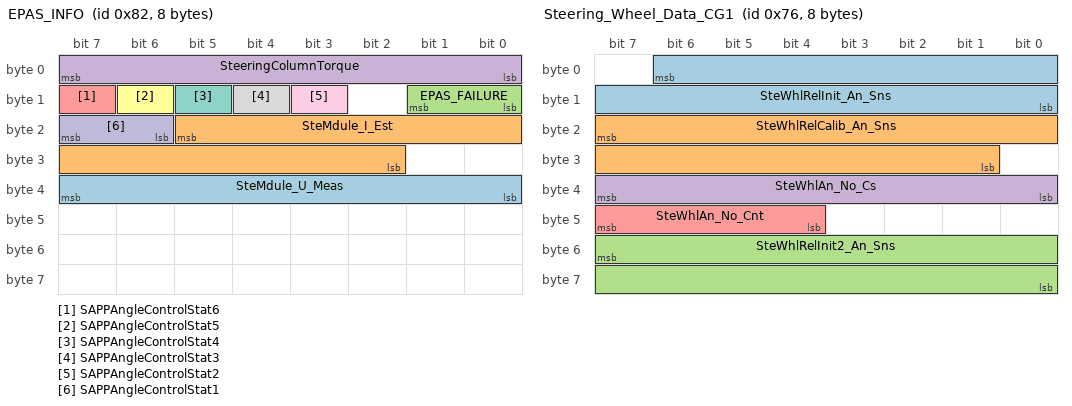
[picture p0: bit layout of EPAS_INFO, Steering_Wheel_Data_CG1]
BO_ 130 EPAS_INFO: 8 XXX
 SG_ SteMdule_U_Meas : 39|8@0+ (0.05,6.0) [0|0] "Volts" XXX
 SG_ SteMdule_I_Est : 21|12@0+ (0.05,-64.0) [0|0] "Amps" XXX
 SG_ EPAS_FAILURE : 9|2@0+ (1,0) [0|0] "" XXX
 SG_ SteeringColumnTorque : 7|8@0+ (0.0625,-8.0) [0|0] "Nm" XXX
 SG_ SAPPAngleControlStat6 : 15|1@0+ (1,0) [0|0] "" XXX
 SG_ SAPPAngleControlStat5 : 14|1@0+ (1,0) [0|0] "" XXX
 SG_ SAPPAngleControlStat4 : 13|1@0+ (1,0) [0|0] "" XXX
 SG_ SAPPAngleControlStat3 : 12|1@0+ (1,0) [0|0] "" XXX
 SG_ SAPPAngleControlStat2 : 11|1@0+ (1,0) [0|0] "" XXX
 SG_ SAPPAngleControlStat1 : 23|2@0+ (1,0) [0|0] "" XXX

BO_ 118 Steering_Wheel_Data_CG1: 8 XXX
 SG_ SteWhlRelInit_An_Sns : 6|15@0+ (0.1,-1600.0) [0|0] "deg" XXX
 SG_ SteWhlRelCalib_An_Sns : 23|15@0+ (0.1,-1600.0) [0|0] "deg" XXX
 SG_ SteWhlRelInit2_An_Sns : 55|16@0+ (0.1,-3200.0) [0|0] "deg" XXX
 SG_ SteWhlAn_No_Cs : 39|8@0+ (1,0) [0|0] "" XXX
 SG_ SteWhlAn_No_Cnt : 47|4@0+ (1,0) [0|0] "Counts" XXX

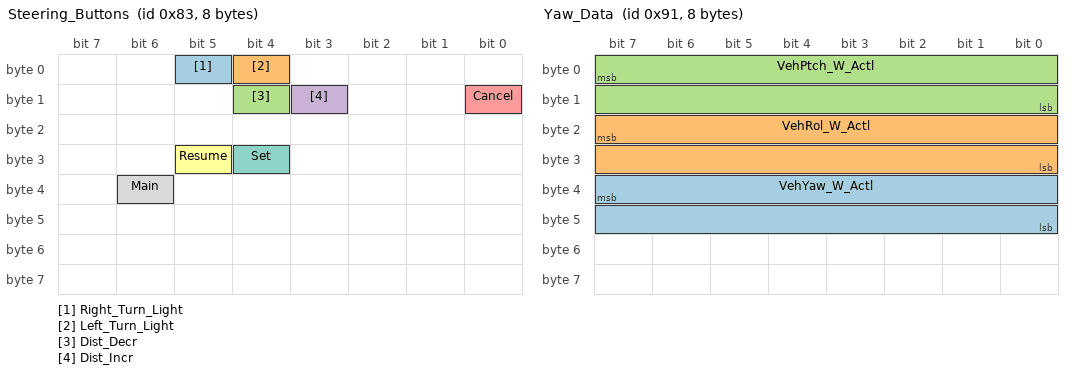
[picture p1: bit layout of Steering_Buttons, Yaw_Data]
BO_ 131 Steering_Buttons: 8 XXX
 SG_ Right_Turn_Light : 5|1@0+ (1,0) [0|0] "" XXX
 SG_ Left_Turn_Light : 4|1@0+ (1,0) [0|0] "" XXX
 SG_ Dist_Decr : 12|1@0+ (1,0) [0|0] "" XXX
 SG_ Dist_Incr : 11|1@0+ (1,0) [0|0] "" XXX
 SG_ Cancel : 8|1@0+ (1,0) [0|0] "" XXX
 SG_ Resume : 29|1@0+ (1,0) [0|0] "" XXX
 SG_ Set : 28|1@0+ (1,0) [0|0] "" XXX
 SG_ Main : 38|1@0+ (1,0) [0|0] "" XXX

BO_ 145 Yaw_Data: 8 XXX
 SG_ VehYaw_W_Actl : 39|16@0+ (0.0002,-6.5) [0|0] "rad/s" XXX
 SG_ VehRol_W_Actl : 23|16@0+ (0.0002,-6.5) [0|0] "rad/s" XXX
 SG_ VehPtch_W_Actl : 7|16@0+ (0.0002,-6.5) [0|0] "rad/s" XXX

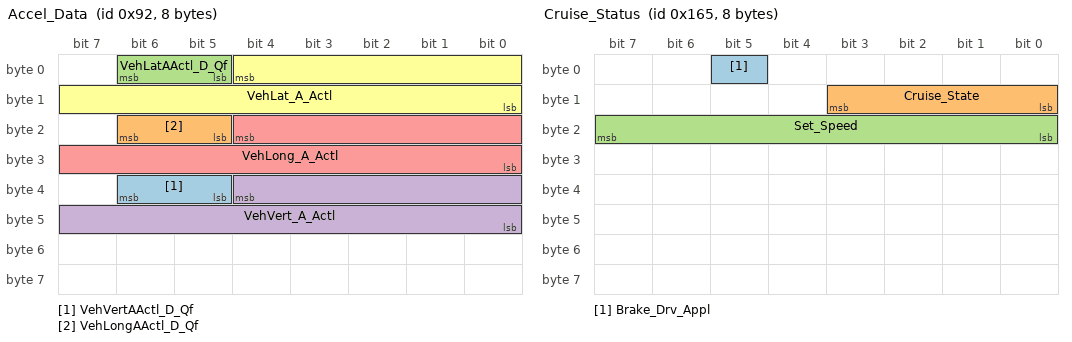
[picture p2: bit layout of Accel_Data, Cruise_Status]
BO_ 146 Accel_Data: 8 XXX
 SG_ VehVertAActl_D_Qf : 38|2@0+ (1,0) [0|0] "" XXX
 SG_ VehLongAActl_D_Qf : 22|2@0+ (1,0) [0|0] "" XXX
 SG_ VehLatAActl_D_Qf : 6|2@0+ (1,0) [0|0] "" XXX
 SG_ VehVert_A_Actl : 36|13@0+ (0.01,-40.0) [0|0] "m/s^2" XXX
 SG_ VehLong_A_Actl : 20|13@0+ (0.01,-40.0) [0|0] "m/s^2" XXX
 SG_ VehLat_A_Actl : 4|13@0+ (0.01,-40.0) [0|0] "m/s^2" XXX

BO_ 357 Cruise_Status: 8 XXX
 SG_ Brake_Drv_Appl : 5|1@0+ (1,0) [0|0] "" XXX
 SG_ Cruise_State : 11|4@0+ (1,0) [0|0] "" XXX
 SG_ Set_Speed : 23|8@0+ (1,0) [0|0] "" XXX

BO_ 516 EngineData_14: 8 XXX
 SG_ ApedPosScal_Pc_Actl : 1|10@0+ (0.1,0) [0|0] "%" XXX

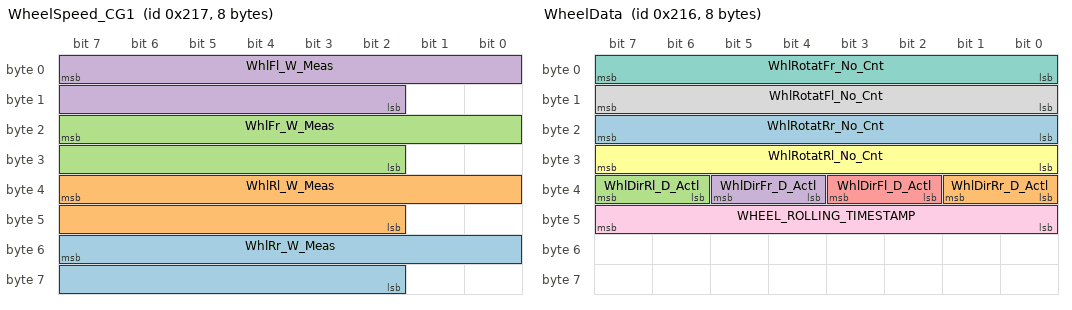
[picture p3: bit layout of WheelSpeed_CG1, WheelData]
BO_ 535 WheelSpeed_CG1: 8 XXX
 SG_ WhlRr_W_Meas : 55|14@0+ (0.04,0) [0|0] "rad/s" XXX
 SG_ WhlRl_W_Meas : 39|14@0+ (0.04,0) [0|0] "rad/s" XXX
 SG_ WhlFr_W_Meas : 23|14@0+ (0.04,0) [0|0] "rad/s" XXX
 SG_ WhlFl_W_Meas : 7|14@0+ (0.04,0) [0|0] "rad/s" XXX

BO_ 534 WheelData: 8 XXX
 SG_ WhlRotatRr_No_Cnt : 23|8@0+ (1,0) [0|0] "" XXX
 SG_ WhlDirRr_D_Actl : 33|2@0+ (1,0) [0|0] "" XXX
 SG_ WhlDirRl_D_Actl : 39|2@0+ (1,0) [0|0] "" XXX
 SG_ WhlDirFr_D_Actl : 37|2@0+ (1,0) [0|0] "" XXX
 SG_ WhlDirFl_D_Actl : 35|2@0+ (1,0) [0|0] "" XXX
 SG_ WhlRotatRl_No_Cnt : 31|8@0+ (1,0) [0|0] "" XXX
 SG_ WhlRotatFr_No_Cnt : 7|8@0+ (1,0) [0|0] "" XXX
 SG_ WhlRotatFl_No_Cnt : 15|8@0+ (1,0) [0|0] "" XXX
 SG_ WHEEL_ROLLING_TIMESTAMP : 47|8@0+ (1,0) [0|0] "" XXX

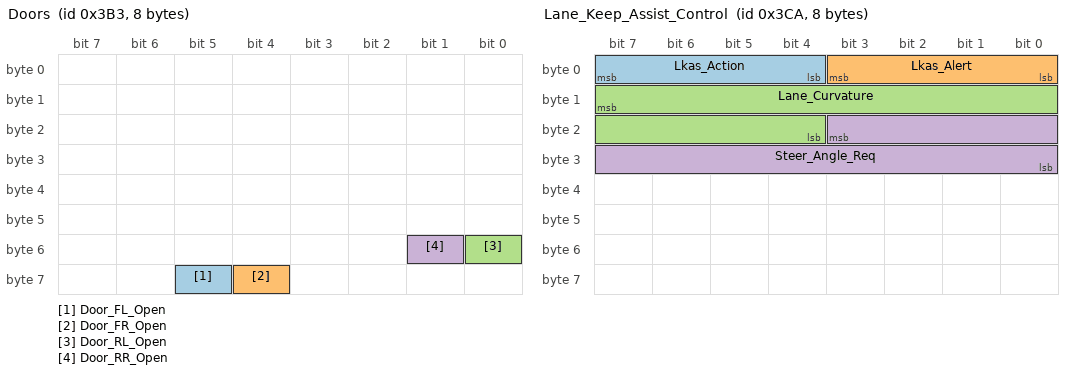
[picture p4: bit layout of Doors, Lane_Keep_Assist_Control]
BO_ 947 Doors: 8 XXX
 SG_ Door_FL_Open : 61|1@0+ (1,0) [0|0] "" XXX
 SG_ Door_FR_Open : 60|1@0+ (1,0) [0|0] "" XXX
 SG_ Door_RL_Open : 48|1@0+ (1,0) [0|0] "" XXX
 SG_ Door_RR_Open : 49|1@0+ (1,0) [0|0] "" XXX

BO_ 963 BCM_to_HS_Body: 8 XXX
 SG_ Brake_Lights : 8|1@0+ (1,0) [0|0] "" XXX

BO_ 970 Lane_Keep_Assist_Control: 8 XXX
 SG_ Lkas_Action : 7|4@0+ (1,0) [0|15] "" XXX
 SG_ Lkas_Alert : 3|4@0+ (1,0) [0|15] "" XXX
 SG_ Lane_Curvature : 15|12@0+ (5e-06,-0.01) [0|0] "1/m" XXX
 SG_ Steer_Angle_Req : 19|12@0+ (0.04297,-88.00445) [0|0] "deg" XXX

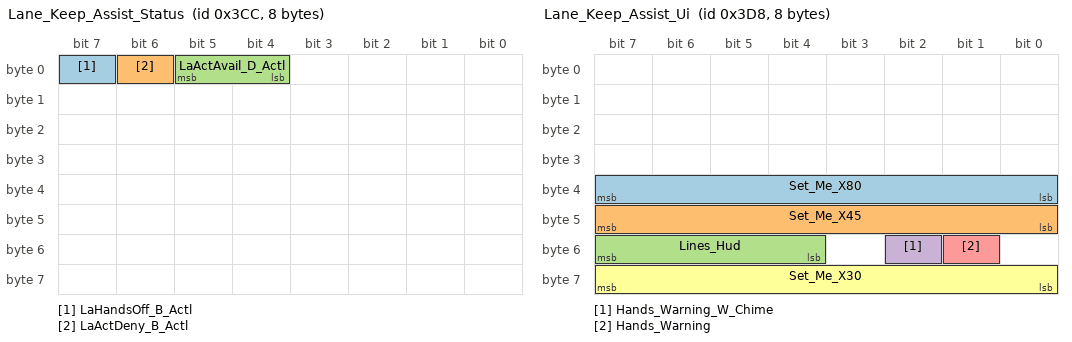
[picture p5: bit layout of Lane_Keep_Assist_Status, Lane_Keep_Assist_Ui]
BO_ 972 Lane_Keep_Assist_Status: 8 XXX
 SG_ LaHandsOff_B_Actl : 7|1@0+ (1,0) [0|0] "" XXX
 SG_ LaActDeny_B_Actl : 6|1@0+ (1,0) [0|0] "" XXX
 SG_ LaActAvail_D_Actl : 5|2@0+ (1,0) [0|0] "" XXX

BO_ 984 Lane_Keep_Assist_Ui: 8 XXX
 SG_ Set_Me_X80 : 39|8@0+ (1,0) [0|255] "" XXX
 SG_ Set_Me_X45 : 47|8@0+ (1,0) [0|255] "" XXX
 SG_ Lines_Hud : 55|4@0+ (1,0) [0|15] "" XXX
 SG_ Hands_Warning_W_Chime : 50|1@0+ (1,0) [0|1] "" XXX
 SG_ Hands_Warning : 49|1@0+ (1,0) [0|1] "" XXX
 SG_ Set_Me_X30 : 63|8@0+ (1,0) [0|255] "" XXX

BU_: PowertrainControlModule InstrumentCluster ElectricPowerSteering AntilockBrakeSystem

CM_ "AUTOGENERATED FILE, DO NOT EDIT";

CM_ "Imported file _comma.dbc starts here";
CM_ "BO_ STEERING_IPAS_COMMA: Copy of msg 614 so we can do angle control while the Park Assist ECU is connected (Panda spoofs 614 with 359 on connector J70). Note that addresses 0x266 and 0x167 are checksum-invariant";

CM_ "BO_ SECONDARY_STEER_ANGLE: ZSS is a high-precision steering angle sensor that can replace the lower resolution sensor in most TSS1 Toyotas. Learn more: https://github.com/commaai/openpilot/wiki/Toyota-Lexus#zorro-steering-sensor-zss";

CM_ "BO_ SDSU: The sDSU is a modified DSU for use in TSS1 Toyotas. Learn more: https://github.com/wocsor/panda/tree/smart_dsu";
CM_ SG_ 767 FD_BUTTON "The follow distance button signal as forwarded by the sdsu";

CM_ "Imported file _toyota_2017.dbc starts here";
CM_ SG_ 36 YAW_RATE "verify";
CM_ SG_ 36 ACCEL_X "x-axis accel";
CM_ SG_ 37 STEER_FRACTION "1/15th of the signal STEER_ANGLE, which is 1.5 deg; note that 0x8 is never set";
CM_ SG_ 37 STEER_RATE "factor is tbd";
CM_ SG_ 466 NEUTRAL_FORCE "force in newtons the engine/electric motors are applying without any acceleration commands or user input";
CM_ SG_ 466 ACC_BRAKING "whether brakes are being actuated from ACC command";
CM_ SG_ 466 ACCEL_NET "net acceleration produced by the system, given ACCEL_CMD, road grade and other factors";
CM_ SG_ 466 CRUISE_STATE "Active state is 8, if standstill is requested will switch to state 11(3 sec timer), after timer is elapsed will switch into state 7(standstill). If plus button was pressed - status 9, minus button pressed - status 10";
CM_ SG_ 467 ACC_FAULTED "1 when ACC is faulted and the PCM disallows engagement";
CM_ SG_ 467 SET_SPEED "43 km/h are shown as 28 mph, so conversion isn't perfect";
CM_ SG_ 467 LOW_SPEED_LOCKOUT "in low speed lockout, system would always disengage below 28mph";
CM_ SG_ 560 BRAKE_PRESSED "another brake pressed?";
CM_ SG_ 581 GAS_PEDAL "it seems slightly filtered";
CM_ SG_ 608 STEER_TORQUE_DRIVER "driver torque";
CM_ SG_ 608 STEER_OVERRIDE "set when driver torque exceeds a certain value";
CM_ SG_ 614 ANGLE "set to measured angle when ipas control isn't active";
CM_ SG_ 643 _COUNTER "only used on cars that use this msg for cruise control";
CM_ SG_ 643 BRAKE_STATUS "only used on cars that use this msg for cruise control";
CM_ SG_ 643 PRECOLLISION_ACTIVE "set 0.5s before any braking";
CM_ SG_ 835 ACC_TYPE "if 2, car is likely to have a permanent low speed lockout. 1 is ok";
CM_ SG_ 835 RADAR_DIRTY "Display Clean Radar Sensor message on HUD";
CM_ SG_ 835 ACC_MALFUNCTION "display ACC fault on dash if set to 1";
CM_ SG_ 835 ACC_CUT_IN "Display blinking yellow lead if set to 1";
CM_ SG_ 835 DISTANCE "Cycle through ACC following distance from long, mid, short when set to 1";
CM_ SG_ 835 ITS_CONNECT_LEAD "Displayed when lead car is capable of ITS Connect";
CM_ SG_ 835 ALLOW_LONG_PRESS "Enable Toyota's factory set speed increment behaviour, available on both metrics cars and imperial unit cars";
CM_ SG_ 835 PERMIT_BRAKING "Original ACC has this going high when a car in front is detected. In openpilot and before the PERMIT_BRAKING name, this was 'SET_ME_1' and is hardcoded to be high. Unsure if only informational or has an effect though existing usage in openpilot is to always set it to 1. Originally 'PMTBRKG' in the leaked toyota_2017_ref_pt.dbc file and name expansion speculated to be PerMiT BRaKinG.";
CM_ SG_ 835 ACCEL_CMD_ALT "Copy of main ACCEL_CMD, but across 8 bits instead of 16 bits like ACCEL_CMD. Unsure if only informational or has an effect. Likely informational as existing openpilot sets this to 0 and no loss of functionality observed. Originally 'AT_RAW' in leaked toyota_2017_ref_pt.dbc file.";
CM_ SG_ 865 GAS_PEDAL_ALT "copy of main GAS_PEDAL. Both use 8 bits. Might indicate that this message is for pedals.";
CM_ SG_ 865 CLUTCH_RELEASED "boolean of clutch for 6MT.";
CM_ SG_ 865 ACC_FAULTED "1 when ACC is faulted and the PCM disallows engagement. Also describes a lockout when the ACC_CONTROL->ACC_MALFUNCTION bit is set.";
CM_ SG_ 921 UI_SET_SPEED "set speed shown in the vehicle's UI with the vehicle's unit";
CM_ SG_ 921 TEMP_ACC_FAULTED "1 when the UI is displaying or playing fault-related alerts or sounds. Also 1 when pressing main on.";
CM_ SG_ 951 BRAKE_LIGHTS_ACC "brake lights when ACC commands decel";
CM_ SG_ 956 GEAR "on 6MT, only R shows.";
CM_ SG_ 1009 UI_SET_SPEED "units seem to be whatever the car is set to";
CM_ SG_ 1041 PCS_INDICATOR "Pre-Collision System Indicator";
CM_ SG_ 1041 PCS_SENSITIVITY "Pre-Collision System Sensitivity";
CM_ SG_ 1041 PCS_DUST "alert: Front Camera Low Visibility Unavailable See Owner's Manual";
CM_ SG_ 1041 PCS_DUST2 "alert: Pre-Collision System Radar Sensor Blocked Unavailable Clean Radar Sensor";
CM_ SG_ 1041 PCS_TEMP "alert: Front Camera Out of Temperature Range Unavailable Wait until Normal Temperature";
CM_ SG_ 1041 PCS_TEMP2 "alert: Pre-Collision System Out of Temperature Range Unavailable See Owner's Manual";
CM_ SG_ 1041 FRD_ADJ "alert: ERROR ADJUSTING FRONT RADAR BEAM";
CM_ SG_ 1042 LDA_SA_TOGGLE "LDA Steering Assist Toggle";
CM_ SG_ 1042 LDW_EXIST "Unclear what this is, it's usually set to 0";
CM_ SG_ 1042 LDA_SENSITIVITY "LDA Sensitivity";
CM_ SG_ 1042 LDA_ON_MESSAGE "Display LDA Turned ON message";
CM_ SG_ 1042 REPEATED_BEEPS "LDA audible warning";
CM_ SG_ 1042 LDA_UNAVAILABLE_QUIET "LDA toggles and sensitivity settings are greyed out if set to 1";
CM_ SG_ 1042 LDA_MESSAGES "Various LDA Messages";
CM_ SG_ 1042 LDA_FRONT_CAMERA_BLOCKED "originally LDAFCVB, LDA related settings are greyed out if set to 1";
CM_ SG_ 1042 TAKE_CONTROL "Please Control Steering Wheel warning";
CM_ SG_ 1042 LANE_SWAY_TOGGLE "Lane Sway Warning System SWS Switch";
CM_ SG_ 1042 LANE_SWAY_WARNING "Lane Sway Warning System Triggered";
CM_ SG_ 1042 LANE_SWAY_FLD "Unknown signal for Lane Sway Warning System, set to 7 on stock system when SWS is enabled, 0 when SWS is disabled";
CM_ SG_ 1042 LANE_SWAY_BUZZER "Similar to TWO_BEEPS";
CM_ SG_ 1042 SET_ME_X01 "empty bit on leaked dbc, always set to 1 during normal operations";
CM_ SG_ 1042 SET_ME_X02 "empty bit on leaked dbc, always set to 2 during normal operations";
CM_ SG_ 1083 STATE "when the dashboard button is pressed, the value changes from zero to non-zero";
CM_ SG_ 1161 SPDVAL1 "Numbers 0-199 is displayed, 200-254 displays circle without number and 255 is for no limit.";
CM_ SG_ 1161 SYNCID1 "counter from 1 to f at 1 Hz";
CM_ SG_ 1161 SPDVAL2 "conditional speed value 70";
CM_ SG_ 1162 SGNNUMP "1 if SPDVAL1 is set, otherwise 0";
CM_ SG_ 1162 SYNCID2 "counter from 1 to f at 1 Hz";
CM_ SG_ 1163 TSREQPD "always 1";
CM_ SG_ 1163 TSRMSW "always 1";
CM_ SG_ 1163 OTSGNNTM "always 3";
CM_ SG_ 1163 NTLVLSPD "always 3";
CM_ SG_ 1163 OVSPNTM "always 3";
CM_ SG_ 1163 OVSPVALL "-5 at start then 2 after 2 seconds";
CM_ SG_ 1163 OVSPVALM "-5 at start then 5 after 2 seconds";
CM_ SG_ 1163 OVSPVALH "-5 at start then 10 after 2 seconds";
CM_ SG_ 1163 TSRSPU "always 1";
CM_ SG_ 1552 UI_SPEED "Does not appear to match dash";
CM_ SG_ 1552 METER_SLIDER_BRIGHTNESS_PCT "Combination display brightness setting, scales from 12 per cent to 100 per cent, reflects combination meter settings only, not linked with headlight state";
CM_ SG_ 1552 METER_SLIDER_LOW_BRIGHTNESS "Combination display low brightness mode, also controls footwell lighting";
CM_ SG_ 1552 METER_SLIDER_DIMMED "Combination display slider not at max, reflects combination meter settings only, not linked with headlight state";
CM_ SG_ 1553 ODOMETER "Unit is dependent upon units signal";
CM_ SG_ 1592 LOCK_STATUS_CHANGED "1 on rising edge of lock/unlocking";
CM_ SG_ 1592 LOCK_STATUS "The next 3 bits always seem to follow this signal.";
CM_ SG_ 1592 LOCKED_VIA_KEYFOB "1 for as long as car is locked with key fob or door handle touch";

CM_ "toyota_new_mc_pt.dbc starts here";

CM_ SG_ 548 BRAKE_PRESSURE "seems prop to pedal force";
CM_ SG_ 548 BRAKE_POSITION "seems proportional to pedal displacement, unclear the max value of 0x1c8";
CM_ SG_ 610 TYPE "seems 1 on Corolla, 0 on all others";
